# eusci_a register map
Vendor: Texas Instruments
Peripheral module from a debugger description file (folder MSP432).
Registers are 16-bit, read-write, no defined reset value unless marked. A register's access mark holds for its fields unless they carry their own. Offsets are as the file gives them; lines under a group give offsets from that group; [hi:lo] are bit positions; {n}, {i} and the like mark numbered series; 'fields as' and 'values as' point back to an identical list; <NAME> marks a mode.

## eUSCI_A
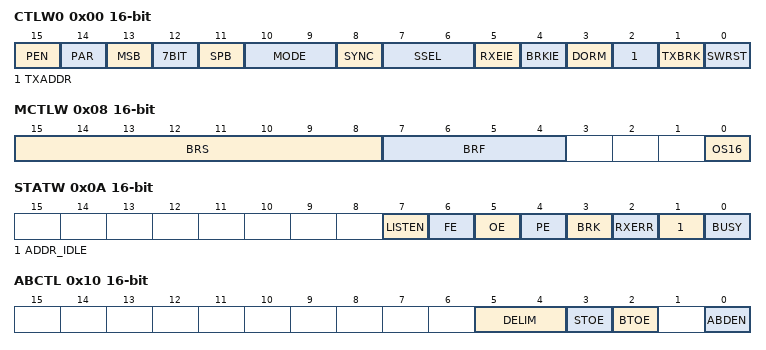
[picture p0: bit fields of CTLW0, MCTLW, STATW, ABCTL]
0x00 CTLW0 — eUSCI_Ax Control Word Register 0
  [15] PEN — Parity enable
    0=PEN__0 (Parity disabled); 1=PEN__1 (Parity enabled)
  [14] PAR — Parity select. UCPAR is not used when parity is disabled.
    0=PAR__0 (Odd parity); 1=PAR__1 (Even parity)
  [13] MSB — MSB first select
    0=MSB__0 (LSB first); 1=MSB__1 (MSB first)
  [12] 7BIT — Character length. Selects 7-bit or 8-bit character length.
    0=7BIT__0 (8-bit data); 1=7BIT__1 (7-bit data)
  [11] SPB — Stop bit select. Number of stop bits.
    0=SPB__0 (One stop bit); 1=SPB__1 (Two stop bits)
  [10:9] MODE — eUSCI_A mode
    0=MODE__0 (UART mode); 1=MODE__1 (Idle-line multiprocessor mode); 2=MODE__2 (Address-bit multiprocessor mode); 3=MODE__3 (UART mode with automatic baud-rate detection)
  [8] SYNC — Synchronous mode enable
    0=SYNC__0 (Asynchronous mode); 1=SYNC__1 (Synchronous mode)
  [7:6] SSEL — eUSCI_A clock source select
    0=SSEL__0 (UCLK); 1=SSEL__1 (ACLK); 2=SSEL__2 (SMCLK)
  [5] RXEIE — Receive erroneous-character interrupt enable
    0=RXEIE__0 (Erroneous characters rejected and UCRXIFG is not set); 1=RXEIE__1 (Erroneous characters received set UCRXIFG)
  [4] BRKIE — Receive break character interrupt enable
    0=BRKIE__0 (Received break characters do not set UCRXIFG); 1=BRKIE__1 (Received break characters set UCRXIFG)
  [3] DORM — Dormant. Puts eUSCI_A into sleep mode
    0=DORM__0 (Not dormant. All received characters set UCRXIFG.); 1=DORM__1 (Dormant)
  [2] TXADDR — Transmit address
    0=TXADDR__0 (Next frame transmitted is data); 1=TXADDR__1 (Next frame transmitted is an address)
  [1] TXBRK — Transmit break
    0=TXBRK__0 (Next frame transmitted is not a break); 1=TXBRK__1 (Next frame transmitted is a break or a break/synch)
  [0] SWRST — Software reset enable
    0=SWRST__0 (Disabled. eUSCI_A reset released for operation); 1=SWRST__1 (Enabled. eUSCI_A logic held in reset state)
0x02 CTLW1 — eUSCI_Ax Control Word Register 1
  [1:0] GLIT — Deglitch time
    0=GLIT__0 (Approximately 2 ns (equivalent of 1 delay element)); 1=GLIT__1 (Approximately 50 ns); 2=GLIT__2 (Approximately 100 ns); 3=GLIT__3 (Approximately 200 ns)
0x06 BRW — eUSCI_Ax Baud Rate Control Word Register
  [15:0] BR — Clock prescaler setting of the Baud rate generator
0x08 MCTLW — eUSCI_Ax Modulation Control Word Register
  [15:8] BRS — Second modulation stage select
  [7:4] BRF — First modulation stage select
  [0] OS16 — Oversampling mode enabled
    0=OS16__0 (Disabled); 1=OS16__1 (Enabled)
0x0A STATW — eUSCI_Ax Status Register
  [7] LISTEN — Listen enable. The UCLISTEN bit selects loopback mode.
    0=LISTEN__0 (Disabled); 1=LISTEN__1 (Enabled. UCAxTXD is internally fed back to the receiver)
  [6] FE — Framing error flag. UCFE is cleared when UCAxRXBUF is read.
    0=FE__0 (No error); 1=FE__1 (Character received with low stop bit)
  [5] OE — Overrun error flag
    0=OE__0 (No error); 1=OE__1 (Overrun error occurred)
  [4] PE — Parity error flag
    0=PE__0 (No error); 1=PE__1 (Character received with parity error)
  [3] BRK — Break detect flag. UCBRK is cleared when UCAxRXBUF is read.
    0=BRK__0 (No break condition); 1=BRK__1 (Break condition occurred)
  [2] RXERR — Receive error flag
    0=RXERR__0 (No receive errors detected); 1=RXERR__1 (Receive error detected)
  [1] ADDR_IDLE — UCADDR: Address received in address-bit multiprocessor mode
  [0] BUSY — eUSCI_A busy
    0=BUSY__0 (eUSCI_A inactive); 1=BUSY__1 (eUSCI_A transmitting or receiving)
0x0C RXBUF — eUSCI_Ax Receive Buffer Register
  [7:0] RXBUF — The receive-data buffer is user accessible and contains the las
0x0E TXBUF — eUSCI_Ax Transmit Buffer Register
  [7:0] TXBUF — The transmit data buffer is user accessible and holds the data
0x10 ABCTL — eUSCI_Ax Auto Baud Rate Control Register
  [5:4] DELIM — Break/synch delimiter length
    0=DELIM__0 (1 bit time); 1=DELIM__1 (2 bit times); 2=DELIM__2 (3 bit times); 3=DELIM__3 (4 bit times)
  [3] STOE — Synch field time out error
    0=STOE__0 (No error); 1=STOE__1 (Length of synch field exceeded measurable time)
  [2] BTOE — Break time out error
    0=BTOE__0 (No error); 1=BTOE__1 (Length of break field exceeded 22 bit times)
  [0] ABDEN — Automatic baud-rate detect enable
    0=ABDEN__0 (Baud-rate detection disabled); 1=ABDEN__1 (Baud-rate detection enabled)
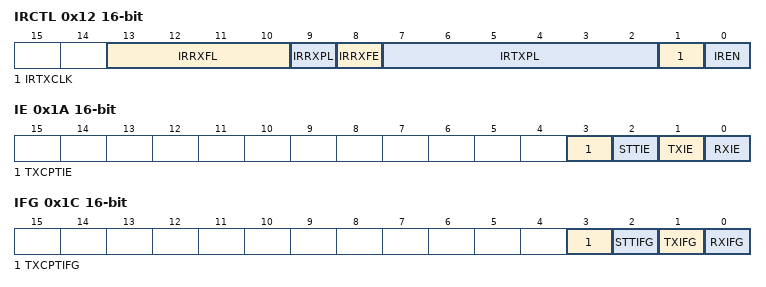
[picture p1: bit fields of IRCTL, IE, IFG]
0x12 IRCTL — eUSCI_Ax IrDA Control Word Register
  [13:10] IRRXFL — Receive filter length
  [9] IRRXPL — IrDA receive input UCAxRXD polarity
    0=IRRXPL__0 (IrDA transceiver delivers a high pulse when a light pulse is se); 1=IRRXPL__1 (IrDA transceiver delivers a low pulse when a light pulse is seen)
  [8] IRRXFE — IrDA receive filter enabled
    0=IRRXFE__0 (Receive filter disabled); 1=IRRXFE__1 (Receive filter enabled)
  [7:2] IRTXPL — Transmit pulse length
  [1] IRTXCLK — IrDA transmit pulse clock select
    0=IRTXCLK__0 (BRCLK); 1=IRTXCLK__1 (BITCLK16 when UCOS16 = 1. Otherwise, BRCLK.)
  [0] IREN — IrDA encoder/decoder enable
    0=IREN__0 (IrDA encoder/decoder disabled); 1=IREN__1 (IrDA encoder/decoder enabled)
0x1A IE — eUSCI_Ax Interrupt Enable Register
  [3] TXCPTIE — Transmit complete interrupt enable
    0=TXCPTIE__0 (Interrupt disabled); 1=TXCPTIE__1 (Interrupt enabled)
  [2] STTIE — Start bit interrupt enable
    0=STTIE__0 (Interrupt disabled); 1=STTIE__1 (Interrupt enabled)
  [1] TXIE — Transmit interrupt enable
    0=TXIE__0 (Interrupt disabled); 1=TXIE__1 (Interrupt enabled)
  [0] RXIE — Receive interrupt enable
    0=RXIE__0 (Interrupt disabled); 1=RXIE__1 (Interrupt enabled)
0x1C IFG — eUSCI_Ax Interrupt Flag Register
  [3] TXCPTIFG — Transmit ready interrupt enable
    0=TXCPTIFG__0 (No interrupt pending); 1=TXCPTIFG__1 (Interrupt pending)
  [2] STTIFG — Start bit interrupt flag
    0=STTIFG__0 (No interrupt pending); 1=STTIFG__1 (Interrupt pending)
  [1] TXIFG — Transmit interrupt flag. UCTXIFG is set when UCAxTXBUF empty.
    0=TXIFG__0 (No interrupt pending); 1=TXIFG__1 (Interrupt pending)
  [0] RXIFG — Receive interrupt flag
    0=RXIFG__0 (No interrupt pending); 1=RXIFG__1 (Interrupt pending)
0x1E IV — eUSCI_Ax Interrupt Vector Register
  [15:0] IV — eUSCI_A interrupt vector value
    0=IV__0 (No interrupt pending); 2=IV__2 (Interrupt Source: Receive buffer full; Interrupt Flag: UCRXIFG;); 4=IV__4 (Interrupt Source: Transmit buffer empty; Interrupt Flag: UCTXIFG); 6=IV__6 (Interrupt Source: Start bit received; Interrupt Flag: UCSTTIFG); 8=IV__8 (Interrupt Source: Transmit complete; Interrupt Flag: UCTXCPTIFG)
